# STM32G0B1 register map
File version: 1.8
CPU: CM0 r0p1, little endian, MPU, no FPU, 2 interrupt priority bits
Registers are 32-bit, read-write, reset 0x0 unless marked. A register's access mark holds for its fields unless they carry their own. Offsets are from the block's base; [hi:lo] are bit positions; {n}, {i} and the like mark numbered series.

## LPTIM1 — Low power timer
Base 0x40007C00
Same registers: LPTIM2 0x40009400
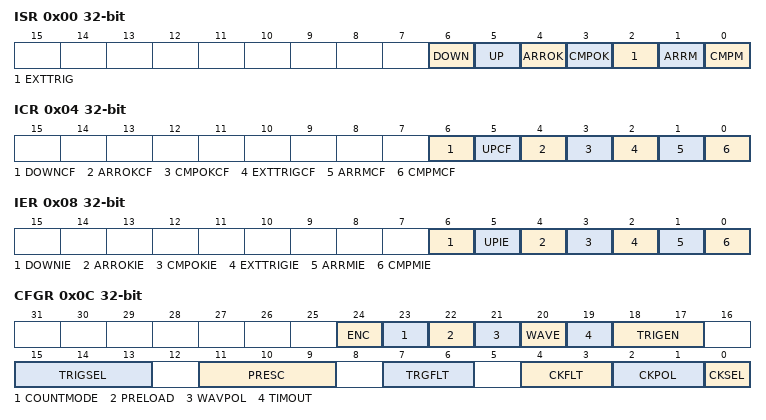
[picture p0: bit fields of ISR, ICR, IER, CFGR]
0x00 ISR ro — Interrupt and Status Register
  [6] DOWN — Counter direction change up to down In Encoder mode, DOWN bit is set by hardware to inform application that the counter direction has changed from up to down. DOWN flag can be cleared by writing 1 to the DOWNCF bit in the LPTIM_ICR register. Note: If the LPTIM does not support encoder mode feature, this bit is reserved. Please refer to .
    1=Set (Counter direction change up to down)
  [5] UP — Counter direction change down to up In Encoder mode, UP bit is set by hardware to inform application that the counter direction has changed from down to up. UP flag can be cleared by writing 1 to the UPCF bit in the LPTIM_ICR register. Note: If the LPTIM does not support encoder mode feature, this bit is reserved. Please refer to .
    1=Set (Counter direction change down to up)
  [4] ARROK — Autoreload register update OK ARROK is set by hardware to inform application that the APB bus write operation to the LPTIM_ARR register has been successfully completed. ARROK flag can be cleared by writing 1 to the ARROKCF bit in the LPTIM_ICR register.
    1=Set (Autoreload register update OK)
  [3] CMPOK — Compare register update OK CMPOK is set by hardware to inform application that the APB bus write operation to the LPTIM_CMP register has been successfully completed.
    1=Set (Compare register update OK)
  [2] EXTTRIG — External trigger edge event EXTTRIG is set by hardware to inform application that a valid edge on the selected external trigger input has occurred. If the trigger is ignored because the timer has already started, then this flag is not set. EXTTRIG flag can be cleared by writing 1 to the EXTTRIGCF bit in the LPTIM_ICR register.
    1=Set (External trigger edge event)
  [1] ARRM — Autoreload match ARRM is set by hardware to inform application that LPTIM_CNT register's value reached the LPTIM_ARR register's value. ARRM flag can be cleared by writing 1 to the ARRMCF bit in the LPTIM_ICR register.
    1=Set (Autoreload match)
  [0] CMPM — Compare match The CMPM bit is set by hardware to inform application that LPTIM_CNT register value reached the LPTIM_CMP register's value.
    1=Set (Compare match)
0x04 ICR wo — Interrupt Clear Register
  [6] DOWNCF — Direction change to down clear flag Writing 1 to this bit clear the DOWN flag in the LPTIM_ISR register. Note: If the LPTIM does not support encoder mode feature, this bit is reserved. Please refer to .
    1=Clear (Direction change to down Clear Flag)
  [5] UPCF — Direction change to UP clear flag Writing 1 to this bit clear the UP flag in the LPTIM_ISR register. Note: If the LPTIM does not support encoder mode feature, this bit is reserved. Please refer to .
    1=Clear (Direction change to up Clear Flag)
  [4] ARROKCF — Autoreload register update OK clear flag Writing 1 to this bit clears the ARROK flag in the LPTIM_ISR register
    1=Clear (Autoreload register update OK Clear Flag)
  [3] CMPOKCF — Compare register update OK clear flag Writing 1 to this bit clears the CMPOK flag in the LPTIM_ISR register
    1=Clear (Compare register update OK Clear Flag)
  [2] EXTTRIGCF — External trigger valid edge clear flag Writing 1 to this bit clears the EXTTRIG flag in the LPTIM_ISR register
    1=Clear (External trigger valid edge Clear Flag)
  [1] ARRMCF — Autoreload match clear flag Writing 1 to this bit clears the ARRM flag in the LPTIM_ISR register
    1=Clear (Autoreload match Clear Flag)
  [0] CMPMCF — Compare match clear flag Writing 1 to this bit clears the CMP flag in the LPTIM_ISR register
    1=Clear (Compare match Clear Flag)
0x08 IER — Interrupt Enable Register
  [6] DOWNIE — Direction change to down Interrupt Enable Note: If the LPTIM does not support encoder mode feature, this bit is reserved. Please refer to .
    0=Disabled (DOWN interrupt disabled); 1=Enabled (DOWN interrupt enabled)
  [5] UPIE — Direction change to UP Interrupt Enable Note: If the LPTIM does not support encoder mode feature, this bit is reserved. Please refer to .
    0=Disabled (UP interrupt disabled); 1=Enabled (UP interrupt enabled)
  [4] ARROKIE — Autoreload register update OK Interrupt Enable
    0=Disabled (ARROK interrupt disabled); 1=Enabled (ARROK interrupt enabled)
  [3] CMPOKIE — Compare register update OK Interrupt Enable
    0=Disabled (CMPOK interrupt disabled); 1=Enabled (CMPOK interrupt enabled)
  [2] EXTTRIGIE — External trigger valid edge Interrupt Enable
    0=Disabled (EXTTRIG interrupt disabled); 1=Enabled (EXTTRIG interrupt enabled)
  [1] ARRMIE — Autoreload match Interrupt Enable
    0=Disabled (ARRM interrupt disabled); 1=Enabled (ARRM interrupt enabled)
  [0] CMPMIE — Compare match Interrupt Enable
    0=Disabled (CMPM interrupt disabled); 1=Enabled (CMPM interrupt enabled)
0x0C CFGR — Configuration Register
  [24] ENC — Encoder mode enable The ENC bit controls the Encoder mode Note: If the LPTIM does not support encoder mode feature, this bit is reserved. Please refer to .
    0=Disabled (Encoder mode disabled); 1=Enabled (Encoder mode enabled)
  [23] COUNTMODE — counter mode enabled The COUNTMODE bit selects which clock source is used by the LPTIM to clock the counter:
    0=Internal (The counter is incremented following each internal clock pulse); 1=External (The counter is incremented following each valid clock pulse on the LPTIM external Input1)
  [22] PRELOAD — Registers update mode The PRELOAD bit controls the LPTIM_ARR and the LPTIM_CMP registers update modality
    0=Immediate (Registers are updated after each APB bus write access); 1=EndOfPeriod (Registers are updated at the end of the current LPTIM period)
  [21] WAVPOL — Waveform shape polarity The WAVEPOL bit controls the output polarity
    0=Positive (The LPTIM output reflects the compare results between LPTIM_ARR and LPTIM_CMP registers); 1=Negative (The LPTIM output reflects the inverse of the compare results between LPTIM_ARR and LPTIM_CMP registers)
  [20] WAVE — Waveform shape The WAVE bit controls the output shape
    0=Inactive (Deactivate Set-once mode, PWM / One Pulse waveform (depending on OPMODE bit)); 1=Active (Activate the Set-once mode)
  [19] TIMOUT — Timeout enable The TIMOUT bit controls the Timeout feature
    0=Disabled (A trigger event arriving when the timer is already started will be ignored); 1=Enabled (A trigger event arriving when the timer is already started will reset and restart the counter)
  [18:17] TRIGEN — Trigger enable and polarity The TRIGEN bits controls whether the LPTIM counter is started by an external trigger or not. If the external trigger option is selected, three configurations are possible for the trigger active edge:
    0=SW (Software trigger (counting start is initiated by software)); 1=Rising edge is the active edge; 2=Falling edge is the active edge; 3=Both edges are active edges
  [15:13] TRIGSEL — Trigger selector The TRIGSEL bits select the trigger source that will serve as a trigger event for the LPTIM among the below 8 available sources: See for details.
    {v}=Trig{v} (lptim_ext_trig{v}) (v=0..7)
  [11:9] PRESC — Clock prescaler The PRESC bits configure the prescaler division factor. It can be one among the following division factors:
    0=Div1 (/1); 1=Div2 (/2); 2=Div4 (/4); 3=Div8 (/8); 4=Div16 (/16); 5=Div32 (/32); 6=Div64 (/64); 7=Div128 (/128)
  [7:6] TRGFLT — Configurable digital filter for trigger The TRGFLT value sets the number of consecutive equal samples that should be detected when a level change occurs on an internal trigger before it is considered as a valid level transition. An internal clock source must be present to use this feature
    0=Immediate (Any trigger active level change is considered as a valid trigger); 1=Clocks2 (Trigger active level change must be stable for at least 2 clock periods before it is considered as valid trigger); 2=Clocks4 (Trigger active level change must be stable for at least 4 clock periods before it is considered as valid trigger); 3=Clocks8 (Trigger active level change must be stable for at least 8 clock periods before it is considered as valid trigger)
  [4:3] CKFLT — Configurable digital filter for external clock The CKFLT value sets the number of consecutive equal samples that should be detected when a level change occurs on an external clock signal before it is considered as a valid level transition. An internal clock source must be present to use this feature
    0=Immediate (Any external clock signal level change is considered as a valid transition); 1=Clocks2 (External clock signal level change must be stable for at least 2 clock periods before it is considered as valid transition); 2=Clocks4 (External clock signal level change must be stable for at least 4 clock periods before it is considered as valid transition); 3=Clocks8 (External clock signal level change must be stable for at least 8 clock periods before it is considered as valid transition)
  [2:1] CKPOL — Clock Polarity If LPTIM is clocked by an external clock source: When the LPTIM is clocked by an external clock source, CKPOL bits is used to configure the active edge or edges used by the counter: If the LPTIM is configured in Encoder mode (ENC bit is set), the encoder sub-mode 1 is active. If the LPTIM is configured in Encoder mode (ENC bit is set), the encoder sub-mode 2 is active. Refer to for more details about Encoder mode sub-modes.
    0=RisingEdge (The rising edge is the active edge used for counting. If LPTIM is in encoder mode: Encoder sub-mode 1 is active.); 1=FallingEdge (The falling edge is the active edge used for counting. If LPTIM is in encoder mode: Encoder sub-mode 2 is active.); 2=Both edges are active edge. If LPTIM is in encoder mode: Encoder sub-mode 3 is active.
  [0] CKSEL — Clock selector The CKSEL bit selects which clock source the LPTIM will use:
    0=Internal (LPTIM is clocked by internal clock source (APB clock or any of the embedded oscillators)); 1=External (LPTIM is clocked by an external clock source through the LPTIM external Input1)
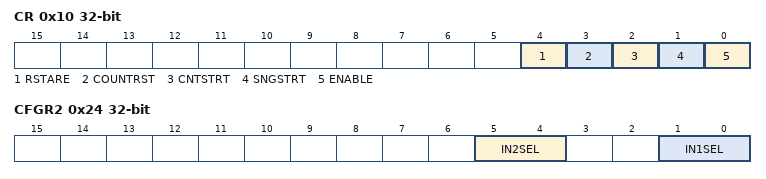
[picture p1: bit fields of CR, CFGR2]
0x10 CR — Control Register
  [4] RSTARE — Reset after read enable This bit is set and cleared by software. When RSTARE is set to '1', any read access to LPTIM_CNT register will asynchronously reset LPTIM_CNT register content.
    0=Disabled (CNT Register reads do not trigger reset); 1=Enabled (CNT Register reads trigger reset of LPTIM)
  [3] COUNTRST — Counter reset This bit is set by software and cleared by hardware. When set to '1' this bit will trigger a synchronous reset of the LPTIM_CNT counter register. Due to the synchronous nature of this reset, it only takes place after a synchronization delay of 3 LPTimer core clock cycles (LPTimer core clock may be different from APB clock). COUNTRST must never be set to '1' by software before it is already cleared to '0' by hardware. Software should consequently check that COUNTRST bit is already cleared to '0' before attempting to set it to '1'.
    on read: 0=Idle (Triggering of reset is possible); 1=Busy (Reset in progress, do not write 1 to this field) | on write: 1=Reset (Trigger synchronous reset of CNT (3 LPTimer core clock cycles))
  [2] CNTSTRT — Timer start in Continuous mode This bit is set by software and cleared by hardware. In case of software start (TRIGEN[1:0] = '00'), setting this bit starts the LPTIM in Continuous mode. If the software start is disabled (TRIGEN[1:0] different than '00'), setting this bit starts the timer in Continuous mode as soon as an external trigger is detected. If this bit is set when a single pulse mode counting is ongoing, then the timer will not stop at the next match between the LPTIM_ARR and LPTIM_CNT registers and the LPTIM counter keeps counting in Continuous mode. This bit can be set only when the LPTIM is enabled. It will be automatically reset by hardware.
    on write: 1=Start (Timer start in Continuous mode)
  [1] SNGSTRT — LPTIM start in Single mode This bit is set by software and cleared by hardware. In case of software start (TRIGEN[1:0] = '00'), setting this bit starts the LPTIM in single pulse mode. If the software start is disabled (TRIGEN[1:0] different than '00'), setting this bit starts the LPTIM in single pulse mode as soon as an external trigger is detected. If this bit is set when the LPTIM is in continuous counting mode, then the LPTIM will stop at the following match between LPTIM_ARR and LPTIM_CNT registers. This bit can only be set when the LPTIM is enabled. It will be automatically reset by hardware.
    on write: 1=Start (LPTIM start in Single mode)
  [0] ENABLE — LPTIM enable The ENABLE bit is set and cleared by software.
    0=Disabled (LPTIM is disabled); 1=Enabled (LPTIM is enabled)
0x14 CMP — Compare Register
  [15:0] CMP — Compare value
0x18 ARR reset 0x1 — Autoreload Register
  [15:0] ARR — Auto reload value
0x1C CNT ro — Counter Register
  [15:0] CNT — Counter value
0x24 CFGR2 — LPTIM configuration register 2
  [5:4] IN2SEL — LPTIM input 2 selection The IN2SEL bits control the LPTIM Input 2 multiplexer, which connect LPTIM Input 2 to one of the available inputs. For connection details refer to . Note: If the LPTIM does not support encoder mode feature, these bits are reserved. Please refer to .
  [1:0] IN1SEL — LPTIM input 1 selection The IN1SEL bits control the LPTIM Input 1 multiplexer, which connects LPTIM Input 1 to one of the available inputs. For connection details refer to .
